# Cortex_M85 register map
Vendor: ARM Ltd.; File version: 1.1
CPU: CM85 r0p0, little endian, MPU, FPU, vendor SysTick, 8 interrupt priority bits
Registers are 32-bit, read-write, no defined reset value unless marked. A register's access mark holds for its fields unless they carry their own. Offsets are from the block's base; [hi:lo] are bit positions; {n}, {i} and the like mark numbered series; 'fields as' and 'values as' point back to an identical list.

## SCB — System Control Block
Base 0xE000ED00
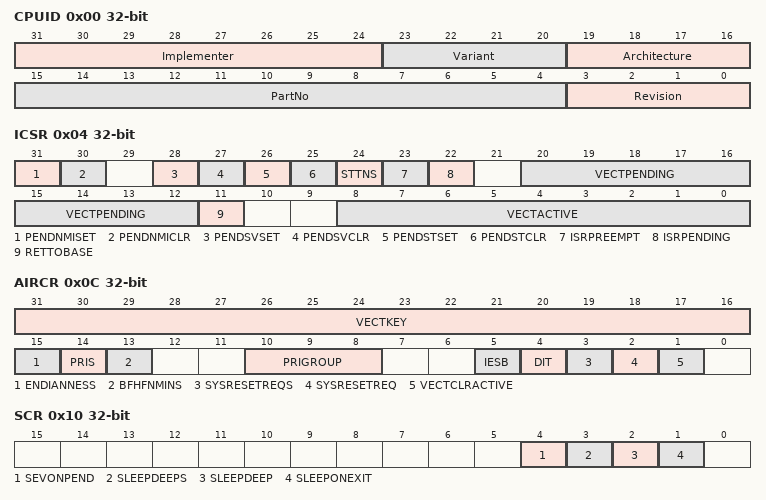
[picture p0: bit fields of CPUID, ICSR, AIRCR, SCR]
0x00 CPUID ro
  [31:24] Implementer, [23:20] Variant, [19:16] Architecture, [15:4] PartNo, [3:0] Revision
0x04 ICSR
  [31] PENDNMISET, [30] PENDNMICLR, [28] PENDSVSET, [27] PENDSVCLR, [26] PENDSTSET, [25] PENDSTCLR, [24] STTNS, [23] ISRPREEMPT, [22] ISRPENDING, [20:12] VECTPENDING, [11] RETTOBASE, [8:0] VECTACTIVE
0x08 VTOR
  [31:7] TBLOFF
0x0C AIRCR
  [31:16] VECTKEY, [15] ENDIANNESS, [14] PRIS, [13] BFHFNMINS, [10:8] PRIGROUP, [5] IESB, [4] DIT, [3] SYSRESETREQS, [2] SYSRESETREQ, [1] VECTCLRACTIVE
0x10 SCR
  [4] SEVONPEND, [3] SLEEPDEEPS, [2] SLEEPDEEP, [1] SLEEPONEXIT
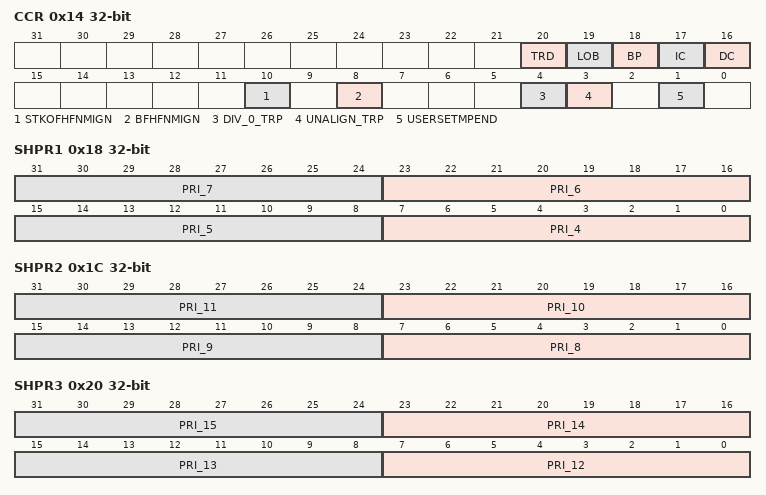
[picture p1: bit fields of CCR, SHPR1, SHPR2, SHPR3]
0x14 CCR
  [20] TRD, [19] LOB, [18] BP, [17] IC, [16] DC, [10] STKOFHFNMIGN, [8] BFHFNMIGN, [4] DIV_0_TRP, [3] UNALIGN_TRP, [1] USERSETMPEND
0x18 SHPR1
  [8n-25:8n-32] PRI_{n} (n=4..7)
0x1C SHPR2
  [8n-57:8n-64] PRI_{n} (n=8..11)
0x20 SHPR3
  [8n-89:8n-96] PRI_{n} (n=12..15)
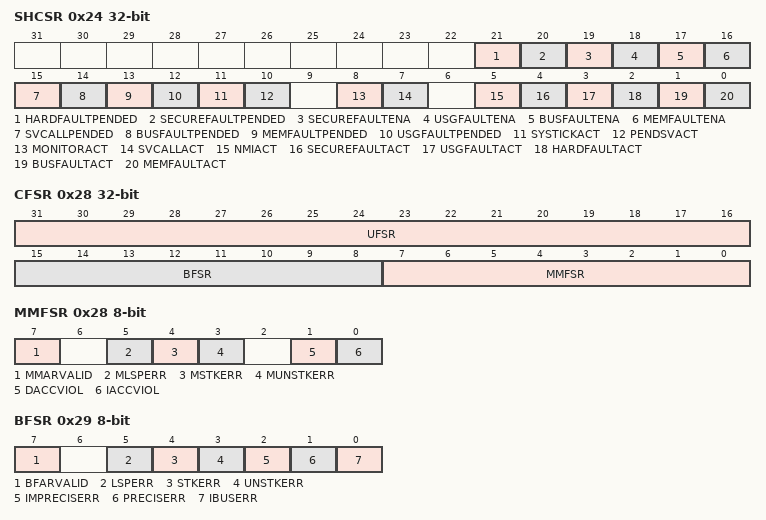
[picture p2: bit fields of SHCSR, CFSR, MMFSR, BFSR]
0x24 SHCSR
  [21] HARDFAULTPENDED, [20] SECUREFAULTPENDED, [19] SECUREFAULTENA, [18] USGFAULTENA, [17] BUSFAULTENA, [16] MEMFAULTENA, [15] SVCALLPENDED, [14] BUSFAULTPENDED, [13] MEMFAULTPENDED, [12] USGFAULTPENDED, [11] SYSTICKACT, [10] PENDSVACT, [8] MONITORACT, [7] SVCALLACT, [5] NMIACT, [4] SECUREFAULTACT, [3] USGFAULTACT, [2] HARDFAULTACT, [1] BUSFAULTACT, [0] MEMFAULTACT
0x28 CFSR
  [31:16] UFSR, [15:8] BFSR, [7:0] MMFSR
0x28 MMFSR 8-bit (alternate view of CFSR)
  [7] MMARVALID, [5] MLSPERR, [4] MSTKERR, [3] MUNSTKERR, [1] DACCVIOL, [0] IACCVIOL
0x29 BFSR 8-bit
  [7] BFARVALID, [5] LSPERR, [4] STKERR, [3] UNSTKERR, [2] IMPRECISERR, [1] PRECISERR, [0] IBUSERR
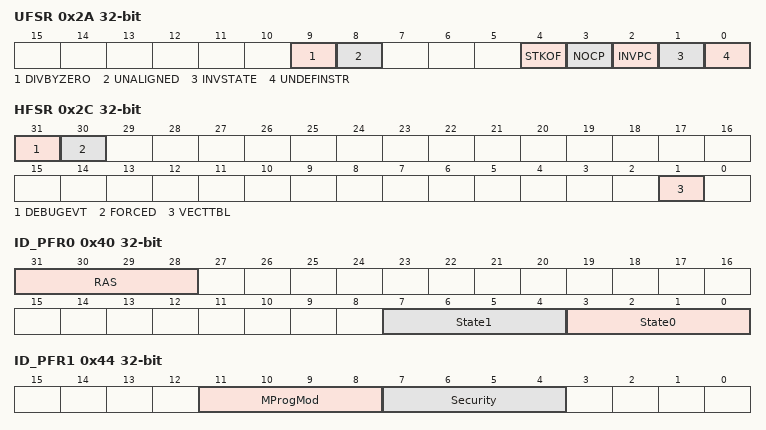
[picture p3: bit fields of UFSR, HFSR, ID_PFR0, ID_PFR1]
0x2A UFSR
  [9] DIVBYZERO, [8] UNALIGNED, [4] STKOF, [3] NOCP, [2] INVPC, [1] INVSTATE, [0] UNDEFINSTR
0x2C HFSR
  [31] DEBUGEVT, [30] FORCED, [1] VECTTBL
0x34 MMFAR
  [31:0] ADDRESS
0x38 BFAR
  [31:0] ADDRESS
0x3C AFSR
  [31:0] IMPLEMENTATION_DEFINED
0x40 ID_PFR0 ro
  [31:28] RAS — RAS one
  [7:4] State1 — State one
  [3:0] State0 — State two
0x44 ID_PFR1 ro
  [11:8] MProgMod, [7:4] Security
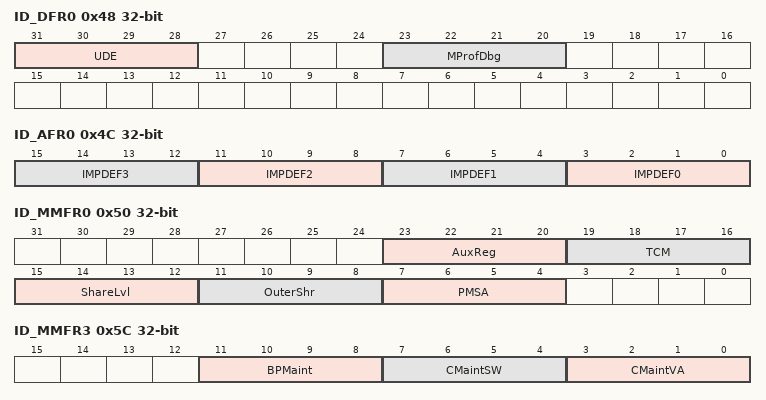
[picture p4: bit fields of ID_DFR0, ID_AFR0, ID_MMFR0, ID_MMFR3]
0x48 ID_DFR0 ro
  [31:28] UDE, [23:20] MProfDbg
0x4C ID_AFR0 ro
  [4n+3:4n] IMPDEF{n} (n=0..3)
0x50 ID_MMFR0 ro
  [23:20] AuxReg, [19:16] TCM, [15:12] ShareLvl, [11:8] OuterShr, [7:4] PMSA
0x54 ID_MMFR1 ro
0x58 ID_MMFR2 ro
  [27:24] WFIStall
0x5C ID_MMFR3 ro
  [11:8] BPMaint, [7:4] CMaintSW, [3:0] CMaintVA
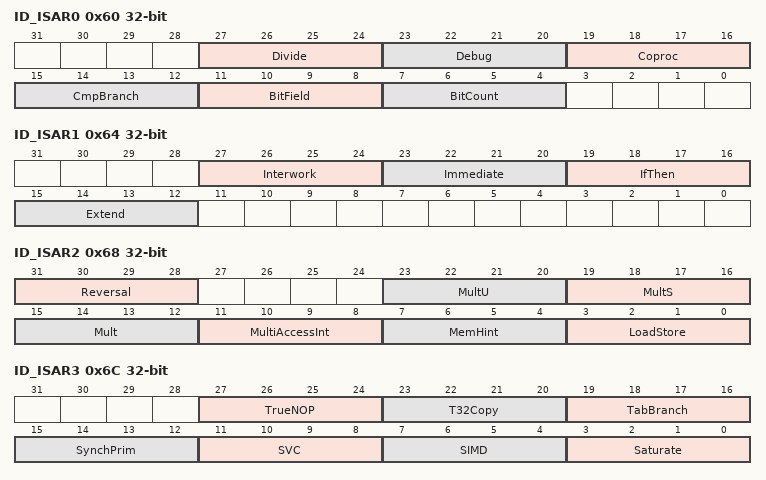
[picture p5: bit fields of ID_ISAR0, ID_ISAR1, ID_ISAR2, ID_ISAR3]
0x60 ID_ISAR0 ro
  [27:24] Divide, [23:20] Debug, [19:16] Coproc, [15:12] CmpBranch, [11:8] BitField, [7:4] BitCount
0x64 ID_ISAR1 ro
  [27:24] Interwork, [23:20] Immediate, [19:16] IfThen, [15:12] Extend
0x68 ID_ISAR2 ro
  [31:28] Reversal, [23:20] MultU, [19:16] MultS, [15:12] Mult, [11:8] MultiAccessInt, [7:4] MemHint, [3:0] LoadStore
0x6C ID_ISAR3 ro
  [27:24] TrueNOP, [23:20] T32Copy, [19:16] TabBranch, [15:12] SynchPrim, [11:8] SVC, [7:4] SIMD, [3:0] Saturate
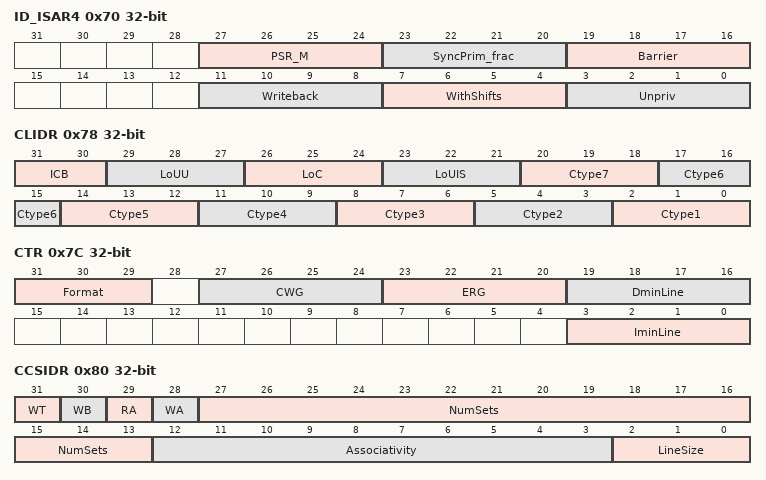
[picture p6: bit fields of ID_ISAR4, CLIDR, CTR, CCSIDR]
0x70 ID_ISAR4 ro
  [27:24] PSR_M, [23:20] SyncPrim_frac, [19:16] Barrier, [11:8] Writeback, [7:4] WithShifts, [3:0] Unpriv
0x74 ID_ISAR5 ro
  [23:20] PACBTI
0x78 CLIDR ro
  [31:30] ICB, [29:27] LoUU, [26:24] LoC, [23:21] LoUIS, [3n-1:3n-3] Ctype{n} (n=1..7)
0x7C CTR ro
  [31:29] Format, [27:24] CWG, [23:20] ERG, [19:16] DminLine, [3:0] IminLine
0x80 CCSIDR ro
  [31] WT
  [30] WB — Writeback
  [29] RA
  [28] WA
  [27:13] NumSets
  [12:3] Associativity
  [2:0] LineSize
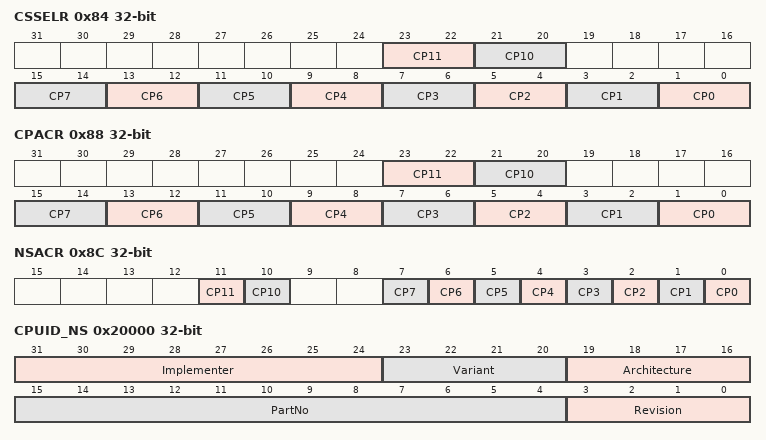
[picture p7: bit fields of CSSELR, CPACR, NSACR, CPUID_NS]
0x84 CSSELR
  [23:22] CP11, [21:20] CP10, [2n+1:2n] CP{n} (n=0..7)
0x88 CPACR
  [23:22] CP11, [21:20] CP10, [2n+1:2n] CP{n} (n=0..7)
0x8C NSACR
  [11] CP11, [10] CP10, [n] CP{n} (n=0..7)
0x20000 CPUID_NS ro
  fields as CPUID
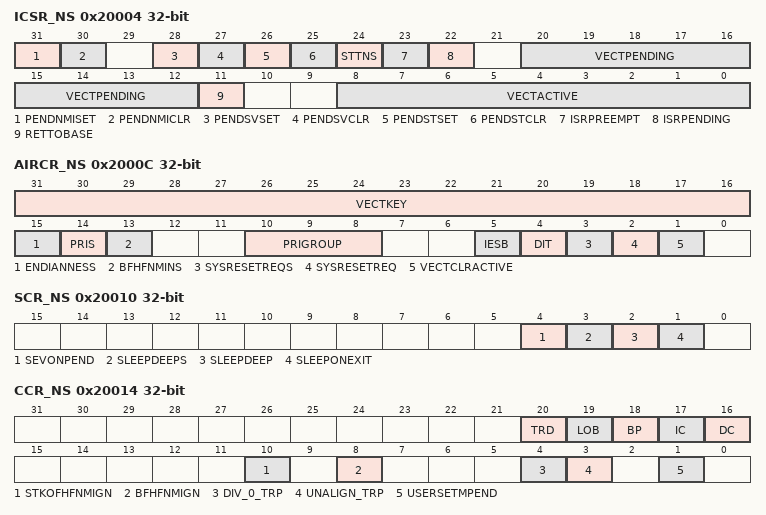
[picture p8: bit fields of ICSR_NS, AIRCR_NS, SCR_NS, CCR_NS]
0x20004 ICSR_NS
  fields as ICSR
0x20008 VTOR_NS
  [31:7] TBLOFF
0x2000C AIRCR_NS — AIRCR_NS2000
  fields as AIRCR
0x20010 SCR_NS
  [4] SEVONPEND, [3] SLEEPDEEPS, [2] SLEEPDEEP, [1] SLEEPONEXIT
0x20014 CCR_NS
  fields as CCR
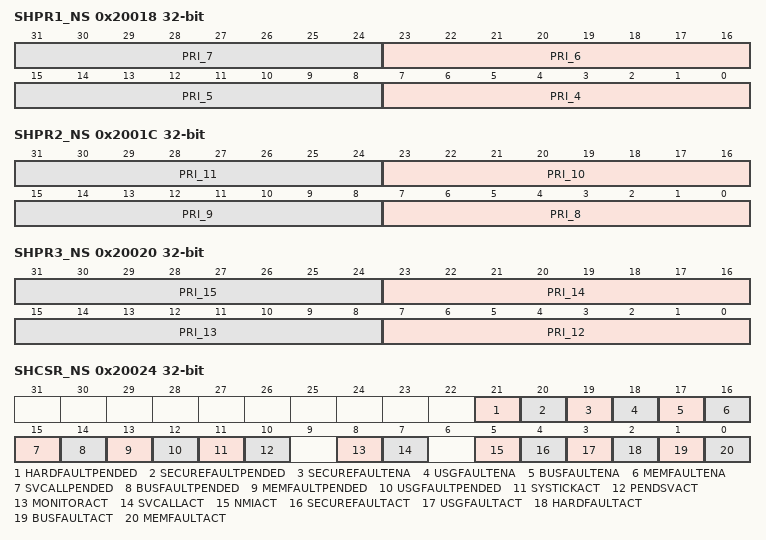
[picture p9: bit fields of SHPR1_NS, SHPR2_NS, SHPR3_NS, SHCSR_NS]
0x20018 SHPR1_NS
  [8n-25:8n-32] PRI_{n} (n=4..7)
0x2001C SHPR2_NS
  [8n-57:8n-64] PRI_{n} (n=8..11)
0x20020 SHPR3_NS
  [8n-89:8n-96] PRI_{n} (n=12..15)
0x20024 SHCSR_NS
  fields as SHCSR
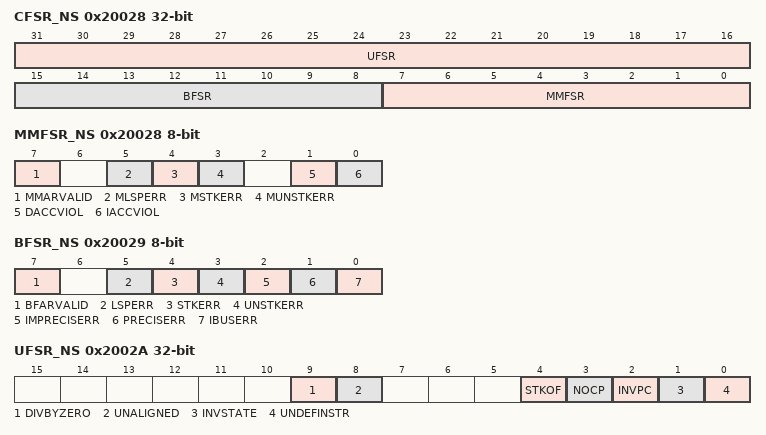
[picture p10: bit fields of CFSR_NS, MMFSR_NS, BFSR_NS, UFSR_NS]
0x20028 CFSR_NS
  [31:16] UFSR, [15:8] BFSR, [7:0] MMFSR
0x20028 MMFSR_NS 8-bit (alternate view of CFSR_NS)
  fields as MMFSR
0x20029 BFSR_NS 8-bit
  fields as BFSR
0x2002A UFSR_NS
  fields as UFSR
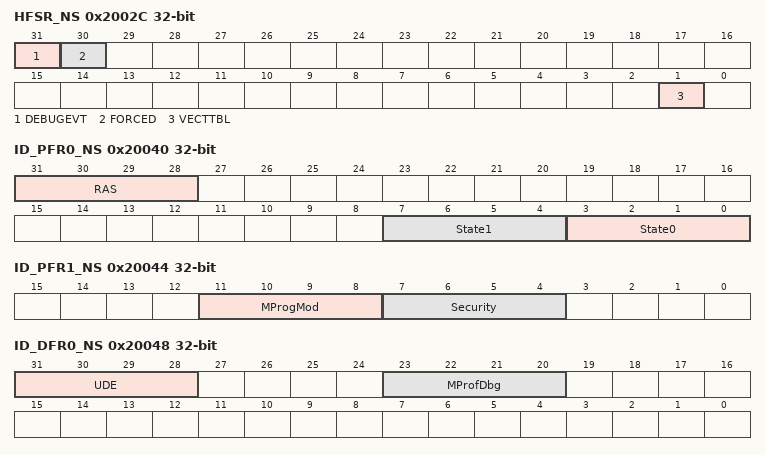
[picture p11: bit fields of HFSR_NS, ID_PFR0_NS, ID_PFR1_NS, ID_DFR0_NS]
0x2002C HFSR_NS
  [31] DEBUGEVT, [30] FORCED, [1] VECTTBL
0x20034 MMFAR_NS
  [31:0] ADDRESS
0x20038 BFAR_NS
  [31:0] ADDRESS
0x2003C AFSR_NS
  [31:0] IMPLEMENTATION_DEFINED
0x20040 ID_PFR0_NS ro
  fields as ID_PFR0
0x20044 ID_PFR1_NS ro
  [11:8] MProgMod, [7:4] Security
0x20048 ID_DFR0_NS ro
  [31:28] UDE, [23:20] MProfDbg
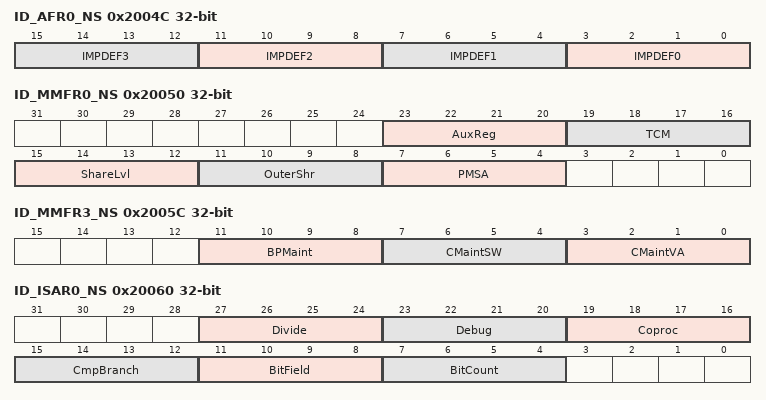
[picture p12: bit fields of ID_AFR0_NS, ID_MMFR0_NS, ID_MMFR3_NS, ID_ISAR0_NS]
0x2004C ID_AFR0_NS ro
  [4n+3:4n] IMPDEF{n} (n=0..3)
0x20050 ID_MMFR0_NS ro
  fields as ID_MMFR0
0x20054 ID_MMFR1_NS ro
0x20058 ID_MMFR2_NS ro
  [27:24] WFIStall
0x2005C ID_MMFR3_NS ro
  [11:8] BPMaint, [7:4] CMaintSW, [3:0] CMaintVA
0x20060 ID_ISAR0_NS ro
  fields as ID_ISAR0
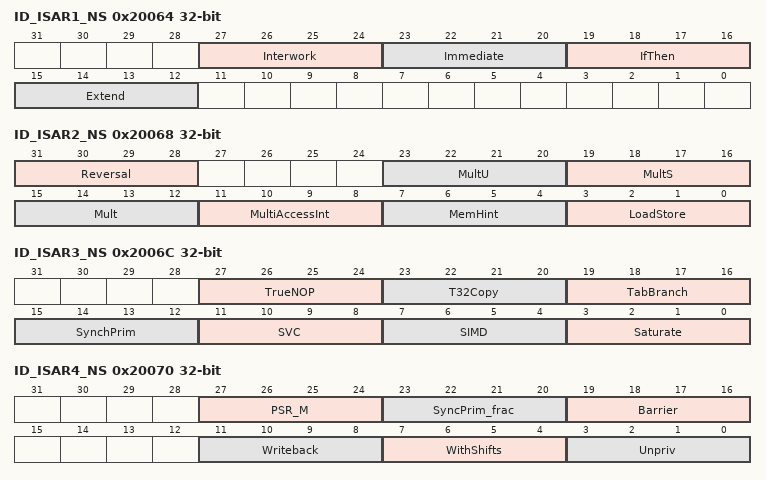
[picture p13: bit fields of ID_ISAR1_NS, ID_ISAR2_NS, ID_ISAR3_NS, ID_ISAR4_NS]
0x20064 ID_ISAR1_NS ro
  [27:24] Interwork, [23:20] Immediate, [19:16] IfThen, [15:12] Extend
0x20068 ID_ISAR2_NS ro
  fields as ID_ISAR2
0x2006C ID_ISAR3_NS ro
  fields as ID_ISAR3
0x20070 ID_ISAR4_NS ro
  fields as ID_ISAR4
0x20074 ID_ISAR5_NS ro
  [23:20] PACBTI
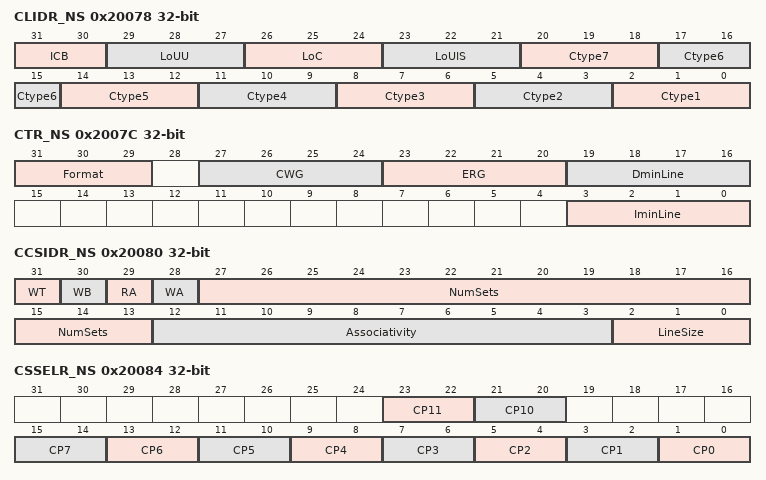
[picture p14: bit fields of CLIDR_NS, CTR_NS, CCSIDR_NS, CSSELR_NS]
0x20078 CLIDR_NS ro
  fields as CLIDR
0x2007C CTR_NS ro
  fields as CTR
0x20080 CCSIDR_NS ro
  fields as CCSIDR
0x20084 CSSELR_NS
  [23:22] CP11, [21:20] CP10, [2n+1:2n] CP{n} (n=0..7)
0x20088 CPACR_NS
  [23:22] CP11, [21:20] CP10, [2n+1:2n] CP{n} (n=0..7)
0x2008C NSACR_NS
  [11] CP11, [10] CP10, [n] CP{n} (n=0..7)

## Notices in the file
Copyright (c) 2024 STMicroelectronics.
SPDX-License-Identifier: Apache-2.0
Licensed under the Apache License, Version 2.0 (the "License");
you may not use this file except in compliance with the License.
You may obtain a copy of the License at
http://www.apache.org/licenses/LICENSE-2.0
Unless required by applicable law or agreed to in writing, software
distributed under the License is distributed on an "AS IS" BASIS,
WITHOUT WARRANTIES OR CONDITIONS OF ANY KIND, either express or implied.
See the License for the specific language governing permissions and
limitations under the License.
